# ing916 register map
Vendor: INGChips; Series: ing916xx; File version: 522
ING916xx reference description for radio MCU with ARM 32-bit Cortex-M3 Microcontroller at 128MHz CPU clock
CPU: CM4 r0p1, little endian, MPU, FPU, VTOR, 5 interrupt priority bits
Registers are 32-bit, read-write, reset 0x0 unless marked. A register's access mark holds for its fields unless they carry their own. Offsets are from the block's base; lines under a group give offsets from that group; [hi:lo] are bit positions; {n}, {i} and the like mark numbered series; 'fields as' and 'values as' point back to an identical list; <NAME> marks a mode.

## Memory map
0x40000000 sys_ctrl size 0x1000
0x40001000 WDT size 0x1000
0x40002000 TIMER0 size 0x1000
0x40003000 TIMER1 size 0x1000
0x40004000 TIMER2 size 0x1000
0x40005000 pwm size 0x1000
0x40006000 io_mux_ctrl size 0x1000
0x40007000 TRNG size 0x1000
0x40008000 PDM size 0x1000
0x40009000 qdec size 0x1000
0x4000A000 key_scanner size 0x1000
0x4000B000 IR size 0x1000
0x4000C000 DMA size 0x1000
0x4000E000 APBSPI size 0x1000
0x4000F000 sadc size 0x1000
0x40010000 I2S size 0x1000
0x40011000 UART0 size 0x1000
0x40012000 UART1 size 0x1000
0x40013000 I2C0 size 0x1000
0x40014000 I2C1 size 0x1000
0x40015000 GPIO0 size 0x1000
0x40016000 GPIO1 size 0x1000
0x40017000 efuse size 0x1000
0x40100000 aon2_ctrl size 0x1000
0x40101000 RTC size 0x1000
0x40102000 aon1_ctrl size 0x1000
0x40130000 AHBAES size 0x1000
0x40140000 I_CACHE_CTRL size 0x1000
0x40141000 D_CACHE_CTRL size 0x1000
0x40150000 FLASH_SPI_CTRL size 0x1000
0x40160000 QSPI size 0x1000
0x40180000 usbc size 0x1000

## WDT
Base 0x40001000
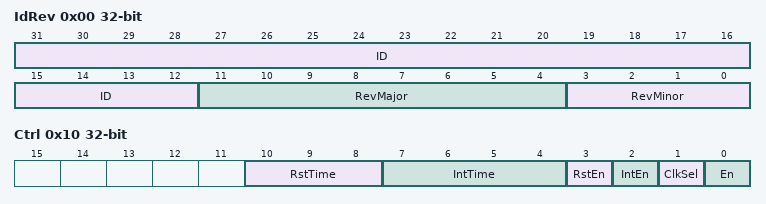
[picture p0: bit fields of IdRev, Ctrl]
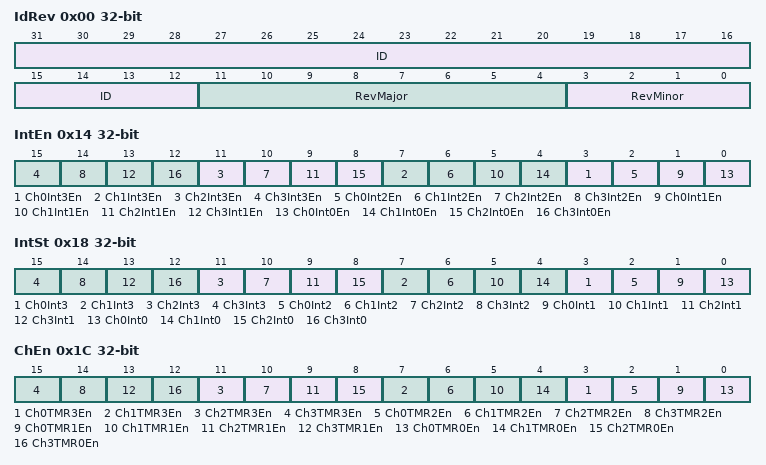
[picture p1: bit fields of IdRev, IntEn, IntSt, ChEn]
0x00 IdRev — reg description:
  [31:12] ID — reg description:
  [11:4] RevMajor — reg description:
  [3:0] RevMinor — reg description:
0x10 Ctrl — reg description:
  [10:8] RstTime — reg description:
  [7:4] IntTime — reg description:
  [3] RstEn — reg description:
  [2] IntEn — reg description:
  [1] ClkSel — reg description:
  [0] En — reg description:
0x14 Restart — reg description:
  [15:0] Restart
0x18 WrEn — reg description:
  [15:0] WEn
0x1C St — reg description:
  [0] IntExpired

## TIMER0
Base 0x40002000
Same registers: TIMER1 0x40003000, TIMER2 0x40004000
0x00 IdRev — reg description:
  [31:12] ID — reg description:
  [11:4] RevMajor — reg description:
  [3:0] RevMinor — reg description:
0x10 Cfg — reg description:
  [2:0] NumCh
0x14 IntEn — reg description:
  [4n+3] Ch{n}Int3En (n=0..3) — reg description:
  [4n+2] Ch{n}Int2En (n=0..3) — reg description:
  [4n+1] Ch{n}Int1En (n=0..3) — reg description:
  [4n] Ch{n}Int0En (n=0..3) — reg description:
0x18 IntSt — reg description:
  [4n+3] Ch{n}Int3 (n=0..3) — reg description:
  [4n+2] Ch{n}Int2 (n=0..3) — reg description:
  [4n+1] Ch{n}Int1 (n=0..3) — reg description:
  [4n] Ch{n}Int0 (n=0..3) — reg description:
0x1C ChEn — reg description:
  [4n+3] Ch{n}TMR3En (n=0..3) — reg description:
  [4n+2] Ch{n}TMR2En (n=0..3) — reg description:
  [4n+1] Ch{n}TMR1En (n=0..3) — reg description:
  [4n] Ch{n}TMR0En (n=0..3) — reg description:
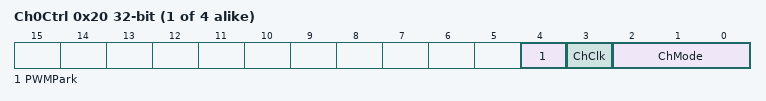
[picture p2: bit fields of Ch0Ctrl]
{0x20+0x10*i} Ch{i}Ctrl (i=0..3) — reg description:
  [4] PWMPark — reg description:
  [3] ChClk — reg description:
  [2:0] ChMode — reg description:
{0x24+0x10*i} Ch{i}Reload (i=0..3) — reg description:
{0x28+0x10*i} Ch{i}Cntr (i=0..3) — reg description:
  [31:0] Counter

## Licence text in the file
Copyright (c) 2022, INGChips All rights reserved. Redistribution and use in source and binary forms, with or without modification, are permitted provided that the following conditions are met: 1. Redistributions of source code must retain the above copyright notice, this list of conditions and the following disclaimer. 2. Redistributions in binary form must reproduce the above copyright notice, this list of conditions and the following disclaimer in the documentation and/or other materials provided with the distribution. 3. Neither the name of Nordic Semiconductor ASA nor the names of its contributors may be used to endorse or promote products derived from this software without specific prior written permission. THIS SOFTWARE IS PROVIDED BY THE COPYRIGHT HOLDERS AND CONTRIBUTORS "AS IS" AND ANY EXPRESS OR IMPLIED WARRANTIES, INCLUDING, BUT NOT LIMITED TO, THE IMPLIED WARRANTIES OF MERCHANTABILITY, AND FITNESS FOR A PARTICULAR PURPOSE ARE DISCLAIMED. IN NO EVENT SHALL NORDIC SEMICONDUCTOR ASA OR CONTRIBUTORS BE LIABLE FOR ANY DIRECT, INDIRECT, INCIDENTAL, SPECIAL, EXEMPLARY, OR CONSEQUENTIAL DAMAGES (INCLUDING, BUT NOT LIMITED TO, PROCUREMENT OF SUBSTITUTE GOODS OR SERVICES; LOSS OF USE, DATA, OR PROFITS; OR BUSINESS INTERRUPTION) HOWEVER CAUSED AND ON ANY THEORY OF LIABILITY, WHETHER IN CONTRACT, STRICT LIABILITY, OR TORT (INCLUDING NEGLIGENCE OR OTHERWISE) ARISING IN ANY WAY OUT OF THE USE OF THIS SOFTWARE, EVEN IF ADVISED OF THE POSSIBILITY OF SUCH DAMAGE.
